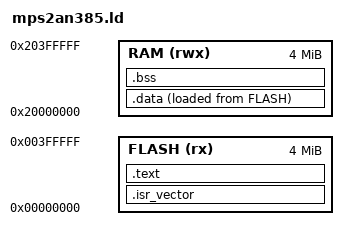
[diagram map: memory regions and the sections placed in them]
/* Linker script for QEMU's mps2-an385 board model. FLASH/RAM origins and
 * sizes match the board's real (QEMU-modeled) memory map -- see
 * qemu/hw/arm/mps2.c and docs/system/arm/mps2.rst: code loads at 0x0,
 * writable RAM starts at 0x20000000.
 */
MEMORY
{
    FLASH (rx)  : ORIGIN = 0x00000000, LENGTH = 4M
    RAM   (rwx) : ORIGIN = 0x20000000, LENGTH = 4M
}

ENTRY(Reset_Handler)

SECTIONS
{
    .isr_vector : {
        KEEP(*(.isr_vector))
    } > FLASH

    .text : {
        *(.text*)
        *(.rodata*)
    } > FLASH

    _sidata = LOADADDR(.data);

    .data : {
        _sdata = .;
        *(.data*)
        _edata = .;
    } > RAM AT> FLASH

    .bss : {
        _sbss = .;
        *(.bss*)
        *(COMMON)
        _ebss = .;
    } > RAM

    _estack = ORIGIN(RAM) + LENGTH(RAM);
}
